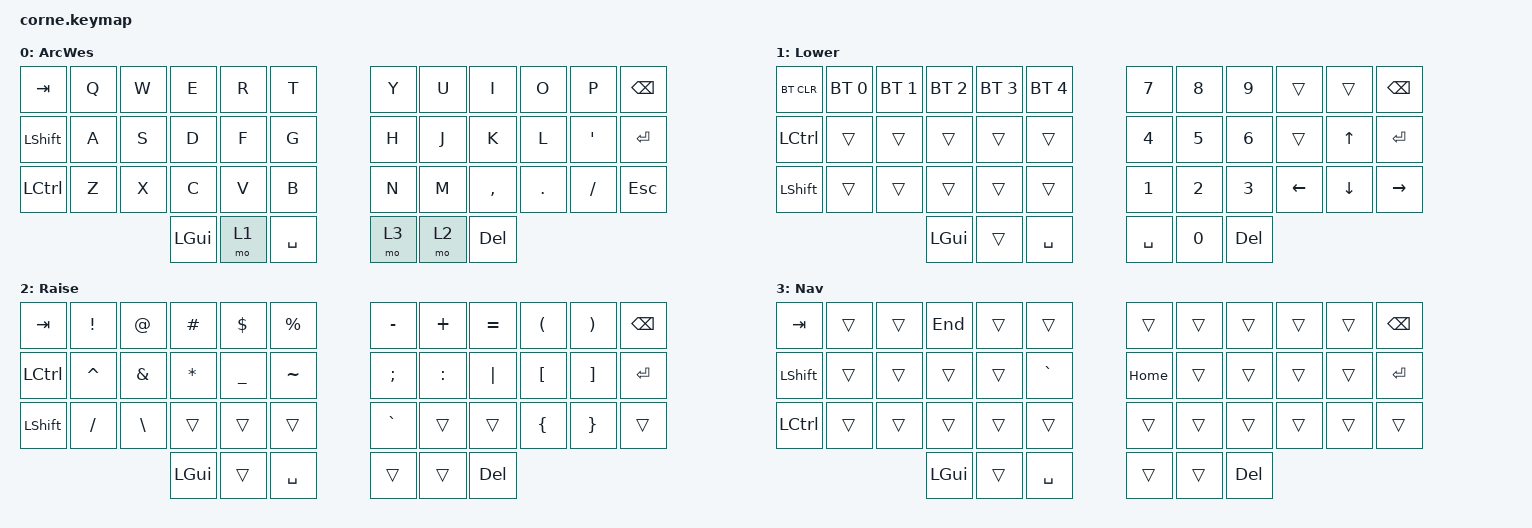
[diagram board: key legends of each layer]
/*
 * Copyright (c) 2020 The ZMK Contributors
 *
 * SPDX-License-Identifier: MIT
 */

#include <behaviors.dtsi>
#include <dt-bindings/zmk/keys.h>
#include <dt-bindings/zmk/bt.h>

/ {
        keymap {
                compatible = "zmk,keymap";

                default_layer {
// -----------------------------------------------------------------------------------------
// |  TAB |  Q  |  W  |  E  |  R  |  T  |   |  Y  |  U   |  I  |  O  |  P  | BKSP |
// | LC(LGUI)  |  A  |  S  |  D  |  F  |  G  |   |  H  |  J   |  K  |  L  |  '  | ENT  |
// | SHFT |  Z  |  X  |  C  |  V  |  B  |   |  N  |  M   |  ,  |  .  |  /  | ESC  |
//                    | GUI | LWR | SPC |   | nav | RSE  | del |
                        display-name = "ArcWes";
                        bindings = <
   &kp TAB   &kp Q &kp W &kp E &kp R &kp T   &kp Y &kp U  &kp I     &kp O   &kp P    &kp BSPC
   &kp LSHFT   &kp A &kp S &kp D &kp F &kp G   &kp H &kp J  &kp K     &kp L   &kp SQT  &kp RET
   &kp LCTRL &kp Z &kp X &kp C &kp V &kp B   &kp N &kp M  &kp COMMA &kp DOT &kp FSLH &kp ESC
                   &kp LGUI    &mo 1 &kp SPACE   &mo 3 &mo 2 &kp DEL
                        >;
                };
                lower_layer {
// -----------------------------------------------------------------------------------------
// | BTCLR| BT1 | BT2 | BT3 | BT4 | BT5 |   |  7  |  8  |  9  |     |     | BKSP |
// |      |     |     |     |     |     |   |  4  |  5  |  6  |     |  UP | ENT  |
// | SHFT |     |     |     |     |     |   |  1  |  2  |  3  | LFT | DWN | RGT  |
//                    | GUI |     | SPC |   | SPC |  0  | ALT |
                        display-name = "Lower";
                        bindings = <
   &bt BT_CLR   &bt BT_SEL 0 &bt BT_SEL 1 &bt BT_SEL 2 &bt BT_SEL 3 &bt BT_SEL 4   &kp N7   &kp N8   &kp N9 &trans    &trans &kp BSPC
   &kp LCTRL       &trans       &trans       &trans       &trans       &trans         &kp N4   &kp N5   &kp N6 &trans    &kp UP &kp RET
   &kp LSHFT    &trans       &trans       &trans       &trans       &trans         &kp N1   &kp N2   &kp N3 &kp LEFT  &kp DOWN &kp RIGHT
                          	          &kp LGUI     &trans       &kp SPACE      &kp SPACE  &kp N0   &kp DEL
                        >;
                };

                raise_layer {
// -----------------------------------------------------------------------------------------
// |  TAB |  !  |  @  |  #  |  $  |  %  |   |  -  |  +  |  =  |  (  |  )  | BKSP |
// | LC(LGUI)  |  ^  |  &  |  *  |  _  |  ~  |   |  ;  |  :  | "|" |  [  |  ]  | ENT  |
// | SHFT |  /  |  \  |  ?   |     |     |   |  `  |     |     |  {  |  }  |      |
//                    | GUI |     | SPC |   | SPC |     | ALT |
                        display-name = "Raise";
                        bindings = <
   &kp  TAB  &kp EXCL  &kp AT   &kp HASH        &kp DLLR    &kp PRCNT   &kp MINUS   &kp PLUS &kp EQUAL &kp LPAR  &kp RPAR   &kp BSPC
   &kp  LCTRL  &kp CARET &kp AMPS &kp ASTERISK &kp UNDER   &kp TILDE   &kp SEMI    &kp COLON&kp PIPE  &kp LBKT  &kp RBKT   &kp RET
   &kp LSHFT &kp FSLH  &kp BSLH &trans          &trans      &trans      &kp GRAVE   &trans   &trans    &kp LBRC  &kp RBRC   &trans
                    	     &kp LGUI &trans   &kp SPACE    &trans   &trans    &kp DEL
                        >;
                };
                nav_layer {
                        display-name = "Nav";
                        bindings = <
   &kp TAB       &trans     &trans  &kp END &trans &trans                          &trans   &trans  &trans &trans    &trans &kp BSPC
   &kp LSHFT      &trans       &trans       &trans       &trans       &kp GRAVE         &kp HOME   &trans   &trans &trans    &trans &kp RET
   &kp LCTRL     &trans       &trans       &trans       &trans       &trans            &trans   &trans   &trans &trans  &trans &trans
                          	          &kp LGUI     &trans       &kp SPACE      &trans  &trans   &kp DEL
                        >;
                };

                extra_2 {
                        status = "reserved";
                };

                extra_3 {
                        status = "reserved";
                };
        };
};
